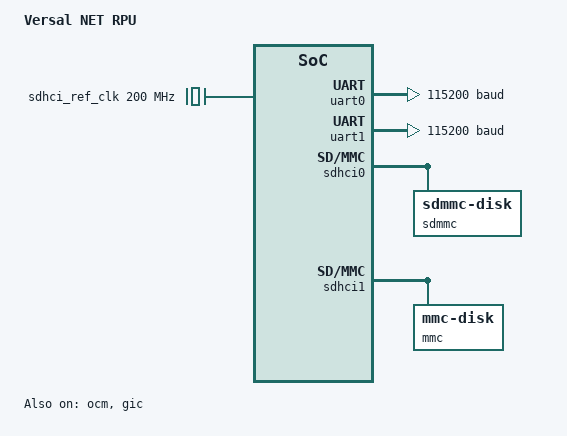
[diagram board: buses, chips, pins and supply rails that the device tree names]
/dts-v1/;

/* node '/' defined in zephyr/dts/common/skeleton.dtsi:9 */
/ {
	#address-cells = < 0x1 >; /* in zephyr/dts/common/skeleton.dtsi:10 */
	#size-cells = < 0x1 >;    /* in zephyr/dts/common/skeleton.dtsi:11 */
	model = "Versal NET RPU"; /* in zephyr/dts/arm/xilinx/versalnet_r52.dtsi:15 */

	/* node '/chosen' defined in zephyr/dts/common/skeleton.dtsi:13 */
	chosen {
		zephyr,sram = &sram0;       /* in zephyr/boards/amd/versalnet_rpu/versalnet_rpu.dts:12 */
		zephyr,console = &uart0;    /* in zephyr/boards/amd/versalnet_rpu/versalnet_rpu.dts:13 */
		zephyr,shell-uart = &uart0; /* in zephyr/boards/amd/versalnet_rpu/versalnet_rpu.dts:14 */
		zephyr,ocm = &ocm;          /* in zephyr/boards/amd/versalnet_rpu/versalnet_rpu.dts:15 */
	};

	/* node '/aliases' defined in zephyr/dts/common/skeleton.dtsi:15 */
	aliases {
	};

	/* node '/soc' defined in zephyr/dts/arm/armv8-r.dtsi:10 */
	soc: soc {
		#address-cells = < 0x1 >;    /* in zephyr/dts/arm/armv8-r.dtsi:11 */
		#size-cells = < 0x1 >;       /* in zephyr/dts/arm/armv8-r.dtsi:12 */
		compatible = "simple-bus";   /* in zephyr/dts/arm/armv8-r.dtsi:13 */
		ranges;                      /* in zephyr/dts/arm/armv8-r.dtsi:14 */
		interrupt-parent = < &gic >; /* in zephyr/dts/arm/xilinx/versalnet_r52.dtsi:40 */

		/* node '/soc/memory@bbf00000' defined in zephyr/dts/vendor/amd/versalnet.dtsi:9 */
		ocm: memory@bbf00000 {
			compatible = "zephyr,memory-region"; /* in zephyr/dts/vendor/amd/versalnet.dtsi:10 */
			reg = < 0xbbf00000 0x100000 >;       /* in zephyr/dts/vendor/amd/versalnet.dtsi:11 */
			zephyr,memory-region = "OCM";        /* in zephyr/dts/vendor/amd/versalnet.dtsi:13 */
			status = "okay";                     /* in zephyr/boards/amd/versalnet_rpu/versalnet_rpu.dts:37 */
		};

		/* node '/soc/uart@f1920000' defined in zephyr/dts/vendor/amd/versalnet.dtsi:16 */
		uart0: uart@f1920000 {
			compatible = "arm,sbsa-uart";       /* in zephyr/dts/vendor/amd/versalnet.dtsi:17 */
			reg = < 0xf1920000 0x4c >;          /* in zephyr/dts/vendor/amd/versalnet.dtsi:18 */
			interrupt-names = "irq_0";          /* in zephyr/dts/vendor/amd/versalnet.dtsi:20 */
			interrupts = < 0x0 0x19 0x2 0xa0 >; /* in zephyr/dts/vendor/amd/versalnet.dtsi:21 */
			status = "okay";                    /* in zephyr/boards/amd/versalnet_rpu/versalnet_rpu.dts:47 */
			current-speed = < 0x1c200 >;        /* in zephyr/boards/amd/versalnet_rpu/versalnet_rpu.dts:48 */
			clock-frequency = < 0x5f5e100 >;    /* in zephyr/boards/amd/versalnet_rpu/versalnet_rpu.dts:49 */
		};

		/* node '/soc/uart@f1930000' defined in zephyr/dts/vendor/amd/versalnet.dtsi:24 */
		uart1: uart@f1930000 {
			compatible = "arm,sbsa-uart";       /* in zephyr/dts/vendor/amd/versalnet.dtsi:25 */
			reg = < 0xf1930000 0x1000 >;        /* in zephyr/dts/vendor/amd/versalnet.dtsi:26 */
			interrupt-names = "irq_1";          /* in zephyr/dts/vendor/amd/versalnet.dtsi:28 */
			interrupts = < 0x0 0x1a 0x2 0xa0 >; /* in zephyr/dts/vendor/amd/versalnet.dtsi:29 */
			status = "okay";                    /* in zephyr/boards/amd/versalnet_rpu/versalnet_rpu.dts:41 */
			current-speed = < 0x1c200 >;        /* in zephyr/boards/amd/versalnet_rpu/versalnet_rpu.dts:42 */
			clock-frequency = < 0x5f5e100 >;    /* in zephyr/boards/amd/versalnet_rpu/versalnet_rpu.dts:43 */
		};

		/* node '/soc/mmc@f1040000' defined in zephyr/dts/vendor/amd/versalnet.dtsi:32 */
		sdhci0: mmc@f1040000 {
			compatible = "xlnx,versal-8.9a";    /* in zephyr/dts/vendor/amd/versalnet.dtsi:33 */
			interrupts = < 0x0 0xb8 0x2 0xa0 >; /* in zephyr/dts/vendor/amd/versalnet.dtsi:35 */
			reg = < 0xf1040000 0x10000 >;       /* in zephyr/dts/vendor/amd/versalnet.dtsi:36 */
			status = "okay";                    /* in zephyr/boards/amd/versalnet_rpu/versalnet_rpu.dts:53 */
			power-delay-ms = < 0xa >;           /* in zephyr/boards/amd/versalnet_rpu/versalnet_rpu.dts:54 */
			clocks = < &sdhci_ref_clk >;        /* in zephyr/boards/amd/versalnet_rpu/versalnet_rpu.dts:55 */

			/* node '/soc/mmc@f1040000/sdmmc' defined in zephyr/dts/vendor/amd/versalnet.dtsi:38 */
			sdmmc {
				compatible = "zephyr,sdmmc-disk"; /* in zephyr/dts/vendor/amd/versalnet.dtsi:39 */
				disk-name = "sd0";                /* in zephyr/dts/vendor/amd/versalnet.dtsi:40 */
			};
		};

		/* node '/soc/mmc@f1050000' defined in zephyr/dts/vendor/amd/versalnet.dtsi:44 */
		sdhci1: mmc@f1050000 {
			compatible = "xlnx,versal-8.9a";    /* in zephyr/dts/vendor/amd/versalnet.dtsi:45 */
			reg = < 0xf1050000 0x10000 >;       /* in zephyr/dts/vendor/amd/versalnet.dtsi:47 */
			interrupts = < 0x0 0xba 0x2 0xa0 >; /* in zephyr/dts/vendor/amd/versalnet.dtsi:48 */
			status = "okay";                    /* in zephyr/boards/amd/versalnet_rpu/versalnet_rpu.dts:59 */
			clocks = < &sdhci_ref_clk >;        /* in zephyr/boards/amd/versalnet_rpu/versalnet_rpu.dts:60 */

			/* node '/soc/mmc@f1050000/mmc' defined in zephyr/dts/vendor/amd/versalnet.dtsi:50 */
			mmc {
				compatible = "zephyr,mmc-disk"; /* in zephyr/dts/vendor/amd/versalnet.dtsi:51 */
				bus-width = < 0x8 >;            /* in zephyr/dts/vendor/amd/versalnet.dtsi:52 */
				disk-name = "mmc0";             /* in zephyr/dts/vendor/amd/versalnet.dtsi:53 */
			};
		};

		/* node '/soc/interrupt-controller@e2000000' defined in zephyr/dts/arm/xilinx/versalnet_r52.dtsi:42 */
		gic: interrupt-controller@e2000000 {
			compatible = "arm,gic-v3",
			             "arm,gic";       /* in zephyr/dts/arm/xilinx/versalnet_r52.dtsi:43 */
			reg = < 0xe2000000 0x10000 >,
			      < 0xe2100000 0x80000 >; /* in zephyr/dts/arm/xilinx/versalnet_r52.dtsi:44 */
			interrupt-controller;         /* in zephyr/dts/arm/xilinx/versalnet_r52.dtsi:46 */
			#interrupt-cells = < 0x4 >;   /* in zephyr/dts/arm/xilinx/versalnet_r52.dtsi:47 */
			status = "okay";              /* in zephyr/dts/arm/xilinx/versalnet_r52.dtsi:48 */
			phandle = < 0x1 >;            /* in zephyr/dts/arm/xilinx/versalnet_r52.dtsi:40 */
		};

		/* node '/soc/memory@0' defined in zephyr/boards/amd/versalnet_rpu/versalnet_rpu.dts:30 */
		sram0: memory@0 {
			compatible = "mmio-sram"; /* in zephyr/boards/amd/versalnet_rpu/versalnet_rpu.dts:31 */
			reg = < 0x0 0x80000000 >; /* in zephyr/boards/amd/versalnet_rpu/versalnet_rpu.dts:32 */
		};
	};

	/* node '/cpus' defined in zephyr/dts/arm/xilinx/versalnet_r52.dtsi:17 */
	cpus {
		#address-cells = < 0x1 >; /* in zephyr/dts/arm/xilinx/versalnet_r52.dtsi:18 */
		#size-cells = < 0x0 >;    /* in zephyr/dts/arm/xilinx/versalnet_r52.dtsi:19 */

		/* node '/cpus/cpu@0' defined in zephyr/dts/arm/xilinx/versalnet_r52.dtsi:21 */
		cpu0: cpu@0 {
			device_type = "cpu";             /* in zephyr/dts/arm/xilinx/versalnet_r52.dtsi:22 */
			compatible = "arm,cortex-r52";   /* in zephyr/dts/arm/xilinx/versalnet_r52.dtsi:23 */
			reg = < 0x0 >;                   /* in zephyr/dts/arm/xilinx/versalnet_r52.dtsi:24 */
			clock-frequency = < 0x5f5e100 >; /* in zephyr/boards/amd/versalnet_rpu/versalnet_rpu.dts:26 */
		};
	};

	/* node '/timer' defined in zephyr/dts/arm/xilinx/versalnet_r52.dtsi:28 */
	arch_timer: timer {
		compatible = "arm,armv8-timer";    /* in zephyr/dts/arm/xilinx/versalnet_r52.dtsi:29 */
		interrupts = < 0x1 0xd 0x2 0xa0 >,
		             < 0x1 0xe 0x2 0xa0 >,
		             < 0x1 0xb 0x2 0xa0 >,
		             < 0x1 0xa 0x2 0xa0 >; /* in zephyr/dts/arm/xilinx/versalnet_r52.dtsi:30 */
		interrupt-parent = < &gic >;       /* in zephyr/dts/arm/xilinx/versalnet_r52.dtsi:34 */
		status = "okay";                   /* in zephyr/dts/arm/xilinx/versalnet_r52.dtsi:35 */
	};

	/* node '/sdhci-ref-clk' defined in zephyr/boards/amd/versalnet_rpu/versalnet_rpu.dts:18 */
	sdhci_ref_clk: sdhci-ref-clk {
		compatible = "fixed-clock";      /* in zephyr/boards/amd/versalnet_rpu/versalnet_rpu.dts:19 */
		clock-frequency = < 0xbebc200 >; /* in zephyr/boards/amd/versalnet_rpu/versalnet_rpu.dts:20 */
		#clock-cells = < 0x0 >;          /* in zephyr/boards/amd/versalnet_rpu/versalnet_rpu.dts:21 */
		phandle = < 0x2 >;               /* in zephyr/boards/amd/versalnet_rpu/versalnet_rpu.dts:55 */
	};
};
